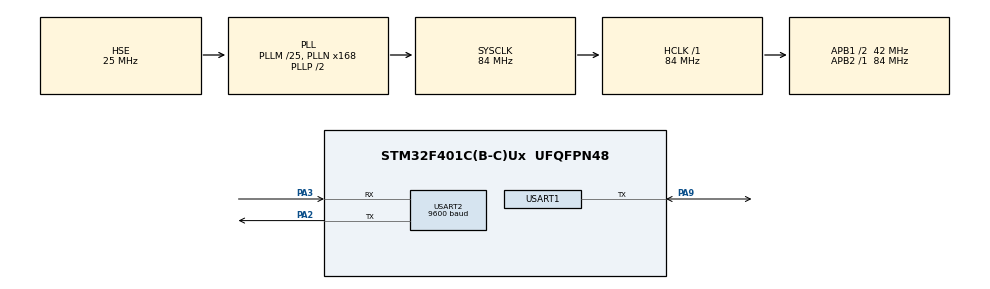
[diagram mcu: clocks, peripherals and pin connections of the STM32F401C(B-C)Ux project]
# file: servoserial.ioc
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Mcu.Family=STM32F4
Mcu.Name=STM32F401C(B-C)Ux
Mcu.Package=UFQFPN48
NVIC.PriorityGroup=NVIC_PRIORITYGROUP_4
PA2.Mode=Asynchronous
PA2.Signal=USART2_TX
PA3.Mode=Asynchronous
PA3.Signal=USART2_RX
PA9.GPIO_PuPd=GPIO_NOPULL
PA9.Mode=Half_duplex(single_wire_mode)
PA9.Signal=USART1_TX
PH0\ -\ OSC_IN.Mode=HSE-External-Oscillator
PH0\ -\ OSC_IN.Signal=RCC_OSC_IN
PH1\ -\ OSC_OUT.Mode=HSE-External-Oscillator
PH1\ -\ OSC_OUT.Signal=RCC_OSC_OUT
ProjectManager.HeapSize=0x200
ProjectManager.StackSize=0x400
ProjectManager.TargetToolchain=CMake
RCC.48MHZClocksFreq_Value=42000000
RCC.AHBFreq_Value=84000000
RCC.APB1CLKDivider=RCC_HCLK_DIV2
RCC.APB1Freq_Value=42000000
RCC.APB1TimFreq_Value=84000000
RCC.APB2Freq_Value=84000000
RCC.APB2TimFreq_Value=84000000
RCC.CortexFreq_Value=84000000
RCC.HCLKFreq_Value=84000000
RCC.HSE_VALUE=25000000
RCC.HSI_VALUE=16000000
RCC.LSE_VALUE=32768
RCC.PLLM=25
RCC.PLLN=168
RCC.PLLSourceVirtual=RCC_PLLSOURCE_HSE
RCC.SYSCLKFreq_VALUE=84000000
RCC.SYSCLKSource=RCC_SYSCLKSOURCE_PLLCLK
RCC.VCOOutputFreq_Value=168000000
USART1.BaudRate=1000000
USART1.VirtualMode=VM_ASYNC
USART2.BaudRate=9600
USART2.VirtualMode=VM_ASYNC
board=custom

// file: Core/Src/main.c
/* USER CODE BEGIN Header */
/**
  ******************************************************************************
  * @file           : main.c
  * @brief          : Main program body
  ******************************************************************************
  * @attention
  *
  * Copyright (c) 2026 STMicroelectronics.
  * All rights reserved.
  *
  * This software is licensed under terms that can be found in the LICENSE file
  * in the root directory of this software component.
  * If no LICENSE file comes with this software, it is provided AS-IS.
  *
  ******************************************************************************
  */
/* USER CODE END Header */
#include "main.h"

/* USER CODE BEGIN Includes */
#include "stdio.h"
#include "string.h"
#include "stdlib.h"
#include "uart.h"
#include "SerialServo.h"

/* USER CODE END Includes */

/* USER CODE BEGIN PD */

//pones los servos que tengas
#define SERVO_ID1    1      // ID del servo 1
#define SERVO_ID2    2      // ID del servo 2

// Para cambiar el ID de un servo: pongo en 1, conecto SOLO ese servo, carga y programo
// Despues vuelve a ponerlo en 0.
#define CAMBIAR_ID   0  //pon esto en 1 cuando queira cambiar un servo
#define ID_ACTUAL    1      // id actual del servo que quieres cambiar
#define ID_NUEVO     2      // ID nuevo que le vas a poner

#define SERVO_SPEED  1000   // pasos/s (0-3400 en STS3215)
#define SERVO_ACC    50     // 0-254

/* USER CODE END PD */

UART_HandleTypeDef huart1;
UART_HandleTypeDef huart2;

void SystemClock_Config(void);
static void MX_GPIO_Init(void);
static void MX_USART1_UART_Init(void);
static void MX_USART2_UART_Init(void);

int main(void)
{

  /* MCU Configuration--------------------------------------------------------*/

  /* Reset of all peripherals, Initializes the Flash interface and the Systick. */
  HAL_Init();

  /* Configure the system clock */
  SystemClock_Config();

  /* Initialize all configured peripherals */
  MX_GPIO_Init();
  MX_USART1_UART_Init();
  MX_USART2_UART_Init();
  /* USER CODE BEGIN 2 */
  int servo_id1 = SERVO_ID1;
  int servo_id2 = SERVO_ID2;

  uartx_write_text(&huart2, "INICIANDO\r\n");
  HAL_Delay(500);                       // dar tiempo a que los servos arranquen
//analizo si queiro cambiar el id al servo
//una vez cambies el ide debes poner  CAMBAIR_ID EN CERO PROGRAMAR DE NUEVO EL MICRO
#if CAMBIAR_ID
   SetID(ID_ACTUAL, ID_NUEVO);
  HAL_Delay(100);
  uartx_write_text(&huart2, Ping(ID_NUEVO) ? "ID cambiado OK\r\n" : "No respondio con el ID nuevo\r\n");
  while (1) {}
#endif

  uartx_write_text(&huart2, Ping(servo_id1) ? "Servo 1 OK\r\n" : "Servo 1 SIN RESPUESTA\r\n");
  uartx_write_text(&huart2, Ping(servo_id2) ? "Servo 2 OK\r\n" : "Servo 2 SIN RESPUESTA\r\n");

  Operation_mode(servo_id1, 0);         // modo posicion
  Operation_speed(servo_id1, SERVO_SPEED);
  Acceleration(servo_id1, SERVO_ACC);
  Torque_enable(servo_id1, 1);

  Operation_mode(servo_id2, 0);
  Operation_speed(servo_id2, SERVO_SPEED);
  Acceleration(servo_id2, SERVO_ACC);
  Torque_enable(servo_id2, 1);
  /* USER CODE END 2 */

  /* Infinite loop */
  /* USER CODE BEGIN WHILE */
  while (1)
  {
//4095 son 360 grados
    Target_location(servo_id1, 1024);
    Target_location(servo_id2, 2024);
    HAL_Delay(1000);
    Target_location(servo_id1, 3072);
    Target_location(servo_id2, 10);
    HAL_Delay(1000);

    /* USER CODE END WHILE */

  }
}

void SystemClock_Config(void)
{
  RCC_OscInitTypeDef RCC_OscInitStruct = {0};
  RCC_ClkInitTypeDef RCC_ClkInitStruct = {0};

  /** Configure the main internal regulator output voltage
  */
  __HAL_RCC_PWR_CLK_ENABLE();
  __HAL_PWR_VOLTAGESCALING_CONFIG(PWR_REGULATOR_VOLTAGE_SCALE2);

  /** Initializes the RCC Oscillators according to the specified parameters
  * in the RCC_OscInitTypeDef structure.
  */
  RCC_OscInitStruct.OscillatorType = RCC_OSCILLATORTYPE_HSE;
  RCC_OscInitStruct.HSEState = RCC_HSE_ON;
  RCC_OscInitStruct.PLL.PLLState = RCC_PLL_ON;
  RCC_OscInitStruct.PLL.PLLSource = RCC_PLLSOURCE_HSE;
  RCC_OscInitStruct.PLL.PLLM = 25;
  RCC_OscInitStruct.PLL.PLLN = 168;
  RCC_OscInitStruct.PLL.PLLP = RCC_PLLP_DIV2;
  RCC_OscInitStruct.PLL.PLLQ = 4;
  if (HAL_RCC_OscConfig(&RCC_OscInitStruct) != HAL_OK)
  {
    Error_Handler();
  }

  /** Initializes the CPU, AHB and APB buses clocks
  */
  RCC_ClkInitStruct.ClockType = RCC_CLOCKTYPE_HCLK|RCC_CLOCKTYPE_SYSCLK
                              |RCC_CLOCKTYPE_PCLK1|RCC_CLOCKTYPE_PCLK2;
  RCC_ClkInitStruct.SYSCLKSource = RCC_SYSCLKSOURCE_PLLCLK;
  RCC_ClkInitStruct.AHBCLKDivider = RCC_SYSCLK_DIV1;
  RCC_ClkInitStruct.APB1CLKDivider = RCC_HCLK_DIV2;
  RCC_ClkInitStruct.APB2CLKDivider = RCC_HCLK_DIV1;

  if (HAL_RCC_ClockConfig(&RCC_ClkInitStruct, FLASH_LATENCY_2) != HAL_OK)
  {
    Error_Handler();
  }
}

static void MX_USART1_UART_Init(void)
{

  huart1.Instance = USART1;
  huart1.Init.BaudRate = 1000000;
  huart1.Init.WordLength = UART_WORDLENGTH_8B;
  huart1.Init.StopBits = UART_STOPBITS_1;
  huart1.Init.Parity = UART_PARITY_NONE;
  huart1.Init.Mode = UART_MODE_TX_RX;
  huart1.Init.HwFlowCtl = UART_HWCONTROL_NONE;
  huart1.Init.OverSampling = UART_OVERSAMPLING_16;
  if (HAL_HalfDuplex_Init(&huart1) != HAL_OK)
  {
    Error_Handler();
  }

}

static void MX_USART2_UART_Init(void)
{

  huart2.Instance = USART2;
  huart2.Init.BaudRate = 9600;
  huart2.Init.WordLength = UART_WORDLENGTH_8B;
  huart2.Init.StopBits = UART_STOPBITS_1;
  huart2.Init.Parity = UART_PARITY_NONE;
  huart2.Init.Mode = UART_MODE_TX_RX;
  huart2.Init.HwFlowCtl = UART_HWCONTROL_NONE;
  huart2.Init.OverSampling = UART_OVERSAMPLING_16;
  if (HAL_UART_Init(&huart2) != HAL_OK)
  {
    Error_Handler();
  }

}

static void MX_GPIO_Init(void)
{

  /* GPIO Ports Clock Enable */
  __HAL_RCC_GPIOH_CLK_ENABLE();
  __HAL_RCC_GPIOA_CLK_ENABLE();

}

void Error_Handler(void)
{
  __disable_irq();
  while (1)
  {
  }
}
